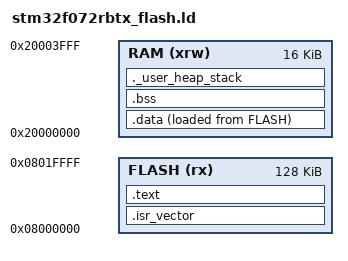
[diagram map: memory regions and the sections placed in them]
MEMORY
{
  FLASH (rx) : ORIGIN = 0x08000000, LENGTH = 128K
  RAM (xrw)  : ORIGIN = 0x20000000, LENGTH = 16K
}

_estack = ORIGIN(RAM) + LENGTH(RAM);
_Min_Heap_Size = 0x200;
_Min_Stack_Size = 0x400;

SECTIONS
{
  .isr_vector :
  {
    KEEP(*(.isr_vector))
  } > FLASH

  .text :
  {
    *(.text*)
    *(.rodata*)
    *(.glue_7)
    *(.glue_7t)
    *(.eh_frame)
    KEEP(*(.init))
    KEEP(*(.fini))
    _etext = .;
  } > FLASH

  _sidata = LOADADDR(.data);

  .data :
  {
    _sdata = .;
    *(.data*)
    _edata = .;
  } > RAM AT > FLASH

  .bss :
  {
    _sbss = .;
    *(.bss*)
    *(COMMON)
    _ebss = .;
  } > RAM

  ._user_heap_stack :
  {
    . = ALIGN(8);
    PROVIDE(end = .);
    PROVIDE(_end = .);
    . = . + _Min_Heap_Size;
    . = . + _Min_Stack_Size;
    . = ALIGN(8);
  } > RAM
}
